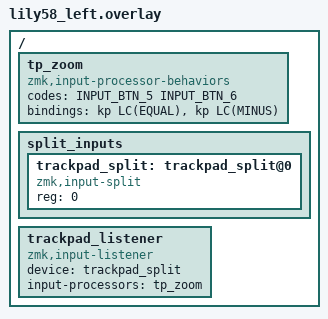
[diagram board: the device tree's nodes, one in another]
/*
 * Left (central) half: receive the right half's trackpad events over the split
 * link and emit HID mouse reports to the host.
 *
 * The zmk,input-split here is the receiving end; it is matched to the
 * peripheral's input-split by reg (one trackpad -> 0).
 */

#include <zephyr/dt-bindings/input/input-event-codes.h>
#include <dt-bindings/zmk/keys.h>

/ {
    /* Pinch-to-zoom. The TPS43 driver turns the chip's ZOOM gesture into
     * BTN_5 (pinch out) / BTN_6 (pinch in) pulses; here they become
     * Ctrl+= / Ctrl+-, which is "zoom" in browsers, editors and viewers. */
    tp_zoom: tp_zoom {
        compatible = "zmk,input-processor-behaviors";
        #input-processor-cells = <0>;
        codes = <INPUT_BTN_5 INPUT_BTN_6>;
        bindings = <&kp LC(EQUAL)>, <&kp LC(MINUS)>;
    };

    split_inputs {
        #address-cells = <1>;
        #size-cells = <0>;

        trackpad_split: trackpad_split@0 {
            compatible = "zmk,input-split";
            reg = <0>;
        };
    };

    trackpad_listener {
        compatible = "zmk,input-listener";
        device = <&trackpad_split>;
        input-processors = <&tp_zoom>;
    };
};
